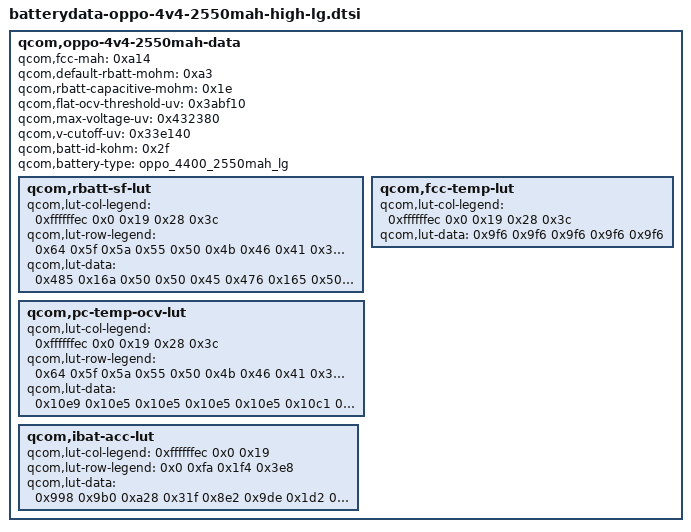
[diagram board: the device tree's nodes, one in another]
/* Copyright (c) 2020, The Linux Foundation. All rights reserved.
*  Copyright (c) 2020, the_shahnawaz_sheikh (sheikhshahnawaz41299).
*
* This program is free software; you can redistribute it and/or modify
* it under the terms of the GNU General Public License version 2 and
* only version 2 as published by the Free Software Foundation.
*
* This program is distributed in the hope that it will be useful,
* but WITHOUT ANY WARRANTY; without even the implied warranty of
* MERCHANTABILITY or FITNESS FOR A PARTICULAR PURPOSE.  See the
* GNU General Public License for more details.
*/

		qcom,oppo-4v4-2550mah-data {
			qcom,fcc-mah = <0xa14>;
			qcom,default-rbatt-mohm = <0xa3>;
			qcom,rbatt-capacitive-mohm = <0x1e>;
			qcom,flat-ocv-threshold-uv = <0x3abf10>;
			qcom,max-voltage-uv = <0x432380>;
			qcom,v-cutoff-uv = <0x33e140>;
			qcom,batt-id-kohm = <0x2f>;
			qcom,battery-type = "oppo_4400_2550mah_lg";

			qcom,rbatt-sf-lut {
				qcom,lut-col-legend = <0xffffffec 0x0 0x19 0x28 0x3c>;
				qcom,lut-row-legend = <0x64 0x5f 0x5a 0x55 0x50 0x4b 0x46 0x41 0x3c 0x37 0x32 0x2d 0x28 0x23 0x1e 0x19 0x14 0x10 0xd 0xb 0xa 0x9 0x8 0x7 0x6 0x5 0x4 0x3 0x2 0x1 0x0>;
				qcom,lut-data = <0x485 0x16a 0x50 0x50 0x45 0x476 0x165 0x50 0x53 0x49 0x452 0x15e 0x66 0x54 0x4c 0x42e 0x156 0x69 0x5a 0x4b 0x408 0x153 0x6a 0x59 0x4e 0x3f3 0x159 0x6f 0x59 0x50 0x3c9 0x144 0x71 0x5f 0x4e 0x3bc 0x144 0x77 0x63 0x50 0x3b6 0x127 0x70 0x5f 0x53 0x3af 0x12b 0x61 0x56 0x4c 0x3b7 0x12a 0x5f 0x50 0x49 0x3c3 0x130 0x61 0x51 0x49 0x3c6 0x131 0x64 0x53 0x4b 0x3da 0x137 0x67 0x57 0x51 0x402 0x139 0x61 0x53 0x49 0x42b 0x13b 0x60 0x4e 0x49 0x467 0x13e 0x64 0x53 0x4b 0x4b5 0x140 0x64 0x56 0x4b 0x4f8 0x169 0x62 0x54 0x49 0x520 0x174 0x63 0x53 0x4e 0x532 0x17d 0x65 0x57 0x4c 0x560 0x17f 0x68 0x56 0x4b 0x579 0x185 0x6c 0x57 0x4e 0x594 0x189 0x71 0x5c 0x4c 0x5b0 0x197 0x6e 0x59 0x4e 0x5f9 0x1a5 0x6d 0x59 0x4b 0x61e 0x1af 0x72 0x5a 0x4e 0x64d 0x1c0 0x7a 0x60 0x53 0x687 0x1f3 0x81 0x68 0x5a 0x673 0x227 0x326 0xaa 0x6b 0x11eb 0x325 0x395 0xe5 0x2f2>;
			};

			qcom,fcc-temp-lut {
				qcom,lut-col-legend = <0xffffffec 0x0 0x19 0x28 0x3c>;
				qcom,lut-data = <0x9f6 0x9f6 0x9f6 0x9f6 0x9f6>;
			};

			qcom,pc-temp-ocv-lut {
				qcom,lut-col-legend = <0xffffffec 0x0 0x19 0x28 0x3c>;
				qcom,lut-row-legend = <0x64 0x5f 0x5a 0x55 0x50 0x4b 0x46 0x41 0x3c 0x37 0x32 0x2d 0x28 0x23 0x1e 0x19 0x14 0x10 0xd 0xb 0xa 0x9 0x8 0x7 0x6 0x5 0x4 0x3 0x2 0x1 0x0>;
				qcom,lut-data = <0x10e9 0x10e5 0x10e5 0x10e5 0x10e5 0x10c1 0x10c5 0x10c5 0x10c5 0x10c5 0x1087 0x107f 0x109b 0x109c 0x1092 0x1052 0x104b 0x1065 0x1068 0x105e 0x1015 0x1017 0x102a 0x102b 0x1029 0xfe7 0xfe4 0xff0 0xff9 0xfee 0xf9e 0xfa6 0xfc1 0xfc2 0xfbf 0xf6d 0xf7b 0xf8e 0xf93 0xf8f 0xf46 0xf4e 0xf65 0xf6c 0xf64 0xf22 0xf22 0xf2c 0xf30 0xf31 0xf06 0xf07 0xf10 0xf14 0xf0f 0xef0 0xeed 0xef5 0xef9 0xef8 0xedd 0xede 0xee5 0xee5 0xee1 0xed0 0xece 0xed4 0xed5 0xed3 0xec7 0xebe 0xec3 0xec5 0xec2 0xebd 0xeaf 0xeb2 0xeaa 0xea0 0xeaf 0xe9d 0xe9f 0xe9b 0xe8d 0xe9f 0xe89 0xe8a 0xe87 0xe79 0xe8f 0xe76 0xe76 0xe73 0xe67 0xe86 0xe74 0xe71 0xe69 0xe5e 0xe81 0xe72 0xe6e 0xe69 0xe5f 0xe7b 0xe71 0xe6d 0xe69 0xe5d 0xe77 0xe70 0xe6e 0xe67 0xe5b 0xe74 0xe6b 0xe69 0xe64 0xe58 0xe71 0xe69 0xe65 0xe61 0xe54 0xe68 0xe5e 0xe56 0xe56 0xe34 0xe62 0xe48 0xe15 0xe1c 0xe14 0xe59 0xe25 0xde8 0xdf4 0xdee 0xe4d 0xdc4 0xdb2 0xdc4 0xdc0 0xe1b 0xd7d 0xcfe 0xd2c 0xd36 0xbb8 0xbb8 0xbb8 0xbb8 0xbb8>;
			};

			qcom,ibat-acc-lut {
				qcom,lut-col-legend = <0xffffffec 0x0 0x19>;
				qcom,lut-row-legend = <0x0 0xfa 0x1f4 0x3e8>;
				qcom,lut-data = <0x998 0x9b0 0xa28 0x31f 0x8e2 0x9de 0x1d2 0x8da 0x9ca 0x0 0x555 0x970>;
			};
		};
